VERSION ""

NS_ :

BS_:

BU_: FrontNode RearNode

BO_ 512 Front_SteeringAngleData: 2 FrontNode
 SG_ SteeringAngleData_angleCentiDegrees : 0|16@1- (1,0) [-10227|10227] "cdeg" Vector__XXX

BO_ 513 Front_SteeringAngleStats: 10 FrontNode
 SG_ SteeringAngleStats_version : 0|8@1+ (1,0) [0|255] "" Vector__XXX
 SG_ SteeringAngleStats_validMask : 8|8@1+ (1,0) [0|255] "" Vector__XXX
 SG_ SteeringAngleStats_rawAngle : 16|16@1+ (1,0) [0|4095] "" Vector__XXX
 SG_ SteeringAngleStats_magnitude : 32|16@1+ (1,0) [0|65535] "" Vector__XXX
 SG_ SteeringAngleStats_agc : 48|8@1+ (1,0) [0|255] "" Vector__XXX
 SG_ SteeringAngleStats_status : 56|8@1+ (1,0) [0|255] "" Vector__XXX
 SG_ SteeringAngleStats_error : 64|16@1- (1,0) [-32768|32767] "" Vector__XXX

BO_ 514 Front_BrakePressure: 4 FrontNode
 SG_ FrontBrakePressure_raw : 7|16@0+ (1,0) [0|4095] "" Vector__XXX
 SG_ RearBrakePressure_raw : 23|16@0+ (1,0) [0|4095] "" Vector__XXX

BO_ 515 Front_Suspension: 4 FrontNode
 SG_ FLSuspension_raw : 7|16@0+ (1,0) [0|4095] "" Vector__XXX
 SG_ FRSuspension_raw : 23|16@0+ (1,0) [0|4095] "" Vector__XXX

BO_ 516 Front_IMU_Data: 54 FrontNode
 SG_ IMU_Data_version : 0|8@1+ (1,0) [0|255] "" Vector__XXX
 SG_ IMU_Data_validMask : 8|8@1+ (1,0) [0|255] "" Vector__XXX
 SG_ IMU_Data_accel_x : 16|32@1- (1,0) [0|0] "m/s^2" Vector__XXX
 SG_ IMU_Data_accel_y : 48|32@1- (1,0) [0|0] "m/s^2" Vector__XXX
 SG_ IMU_Data_accel_z : 80|32@1- (1,0) [0|0] "m/s^2" Vector__XXX
 SG_ IMU_Data_angular_vel_x : 112|32@1- (1,0) [0|0] "rad/s" Vector__XXX
 SG_ IMU_Data_angular_vel_y : 144|32@1- (1,0) [0|0] "rad/s" Vector__XXX
 SG_ IMU_Data_angular_vel_z : 176|32@1- (1,0) [0|0] "rad/s" Vector__XXX
 SG_ IMU_Data_linear_accel_x : 208|32@1- (1,0) [0|0] "m/s^2" Vector__XXX
 SG_ IMU_Data_linear_accel_y : 240|32@1- (1,0) [0|0] "m/s^2" Vector__XXX
 SG_ IMU_Data_linear_accel_z : 272|32@1- (1,0) [0|0] "m/s^2" Vector__XXX
 SG_ IMU_Data_rotation_i : 304|32@1- (1,0) [0|0] "" Vector__XXX
 SG_ IMU_Data_rotation_j : 336|32@1- (1,0) [0|0] "" Vector__XXX
 SG_ IMU_Data_rotation_k : 368|32@1- (1,0) [0|0] "" Vector__XXX
 SG_ IMU_Data_rotation_real : 400|32@1- (1,0) [0|0] "" Vector__XXX

BO_ 517 Front_IMU_Stats: 12 FrontNode
 SG_ IMU_Stats_version : 0|8@1+ (1,0) [0|255] "" Vector__XXX
 SG_ IMU_Stats_validMask : 8|8@1+ (1,0) [0|255] "" Vector__XXX
 SG_ IMU_Stats_error : 16|16@1- (1,0) [-32768|32767] "" Vector__XXX
 SG_ IMU_Stats_accelAccuracy : 32|8@1+ (1,0) [0|255] "" Vector__XXX
 SG_ IMU_Stats_gyroAccuracy : 40|8@1+ (1,0) [0|255] "" Vector__XXX
 SG_ IMU_Stats_linearAccelAccuracy : 48|8@1+ (1,0) [0|255] "" Vector__XXX
 SG_ IMU_Stats_rotationAccuracy : 56|8@1+ (1,0) [0|255] "" Vector__XXX
 SG_ IMU_Stats_rotation_acc_rad : 64|32@1- (1,0) [0|0] "rad" Vector__XXX

BO_ 256 Rear_Suspension: 4 RearNode
 SG_ RLSuspension_raw : 7|16@0+ (1,0) [0|4095] "" Vector__XXX
 SG_ RRSuspension_raw : 23|16@0+ (1,0) [0|4095] "" Vector__XXX

BO_ 257 Rear_ThrottlePosition: 2 RearNode
 SG_ ThrottlePos_raw : 7|16@0+ (1,0) [0|4095] "" Vector__XXX

BO_ 258 Rear_IRCVTTempData: 8 RearNode
 SG_ IRCVTTempData_ambientCentiDegrees : 0|32@1- (1,0) [-2147483648|2147483647] "cdeg" Vector__XXX
 SG_ IRCVTTempData_objectCentiDegrees : 32|32@1- (1,0) [-2147483648|2147483647] "cdeg" Vector__XXX

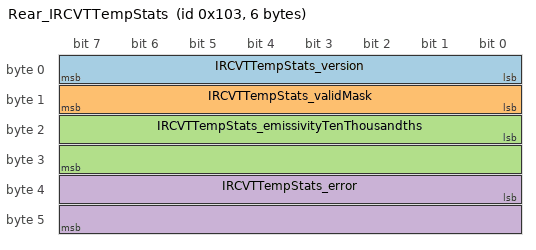
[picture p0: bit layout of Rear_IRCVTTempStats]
BO_ 259 Rear_IRCVTTempStats: 6 RearNode
 SG_ IRCVTTempStats_version : 0|8@1+ (1,0) [0|255] "" Vector__XXX
 SG_ IRCVTTempStats_validMask : 8|8@1+ (1,0) [0|255] "" Vector__XXX
 SG_ IRCVTTempStats_emissivityTenThousandths : 16|16@1+ (1,0) [0|10000] "" Vector__XXX
 SG_ IRCVTTempStats_error : 32|16@1- (1,0) [-32768|32767] "" Vector__XXX

BO_ 260 Rear_RPMData: 8 RearNode
 SG_ WheelSpeedRpmData_milliRpm : 0|32@1- (1,0) [-2147483648|2147483647] "milli_rpm" Vector__XXX
 SG_ EngineRpmData_milliRpm : 32|32@1- (1,0) [-2147483648|2147483647] "milli_rpm" Vector__XXX

BO_ 261 Rear_RPMStats: 34 RearNode
 SG_ WheelSpeedRpmStats_version : 0|8@1+ (1,0) [0|255] "" Vector__XXX
 SG_ WheelSpeedRpmStats_validMask : 8|8@1+ (1,0) [0|255] "" Vector__XXX
 SG_ WheelSpeedRpmStats_rawAdc : 16|16@1+ (1,0) [0|4095] "" Vector__XXX
 SG_ WheelSpeedRpmStats_rawAngle : 32|16@1+ (1,0) [0|4095] "" Vector__XXX
 SG_ WheelSpeedRpmStats_angleCentiDegrees : 48|16@1+ (1,0) [0|35999] "cdeg" Vector__XXX
 SG_ WheelSpeedRpmStats_sampleIntervalMicros : 64|32@1+ (1,0) [0|4294967295] "us" Vector__XXX
 SG_ WheelSpeedRpmStats_error : 96|16@1- (1,0) [-32768|32767] "" Vector__XXX
 SG_ EngineRpmStats_version : 112|8@1+ (1,0) [0|255] "" Vector__XXX
 SG_ EngineRpmStats_validMask : 120|8@1+ (1,0) [0|255] "" Vector__XXX
 SG_ EngineRpmStats_pulseIntervalMicros : 128|32@1+ (1,0) [0|4294967295] "us" Vector__XXX
 SG_ EngineRpmStats_sampleAgeMicros : 160|32@1+ (1,0) [0|4294967295] "us" Vector__XXX
 SG_ EngineRpmStats_acceptedPulseCount : 192|32@1+ (1,0) [0|4294967295] "" Vector__XXX
 SG_ EngineRpmStats_rejectedPulseCount : 224|32@1+ (1,0) [0|4294967295] "" Vector__XXX
 SG_ EngineRpmStats_error : 256|16@1- (1,0) [-32768|32767] "" Vector__XXX

SIG_VALTYPE_ 516 IMU_Data_accel_x : 1;
SIG_VALTYPE_ 516 IMU_Data_accel_y : 1;
SIG_VALTYPE_ 516 IMU_Data_accel_z : 1;
SIG_VALTYPE_ 516 IMU_Data_angular_vel_x : 1;
SIG_VALTYPE_ 516 IMU_Data_angular_vel_y : 1;
SIG_VALTYPE_ 516 IMU_Data_angular_vel_z : 1;
SIG_VALTYPE_ 516 IMU_Data_linear_accel_x : 1;
SIG_VALTYPE_ 516 IMU_Data_linear_accel_y : 1;
SIG_VALTYPE_ 516 IMU_Data_linear_accel_z : 1;
SIG_VALTYPE_ 516 IMU_Data_rotation_i : 1;
SIG_VALTYPE_ 516 IMU_Data_rotation_j : 1;
SIG_VALTYPE_ 516 IMU_Data_rotation_k : 1;
SIG_VALTYPE_ 516 IMU_Data_rotation_real : 1;
SIG_VALTYPE_ 517 IMU_Stats_rotation_acc_rad : 1;
